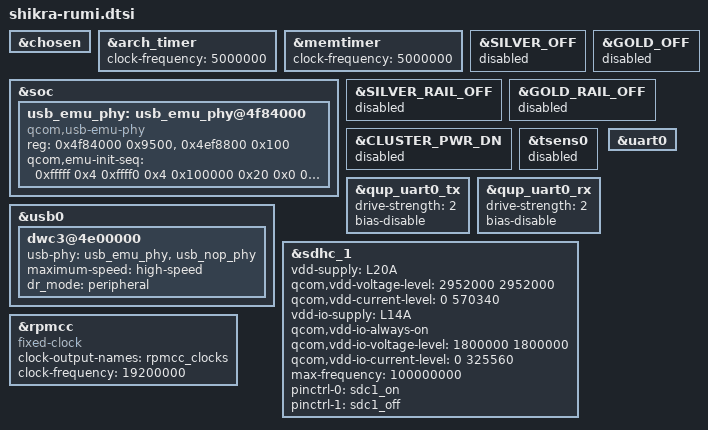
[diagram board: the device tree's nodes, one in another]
// SPDX-License-Identifier: BSD-3-Clause
/*
 * Copyright (c) Qualcomm Technologies, Inc. and/or its subsidiaries.
 */
&chosen {
};

&arch_timer {
	clock-frequency = <5000000>;
};

&memtimer {
	clock-frequency = <5000000>;
};

&soc {
	usb_emu_phy: usb_emu_phy@4f84000 {
		     compatible = "qcom,usb-emu-phy";
		     reg = <0x4f84000 0x9500>,
			 <0x4ef8800 0x100>;
		     reg-names = "base", "qscratch_base";

		     qcom,emu-init-seq = <0xfffff 0x4
			     0xffff0 0x4
			     0x100000 0x20
			     0x0 0x20
			     0x000101F0 0x20
			     0x00100000 0x3c
			     0x0 0x3c
			     0x0 0x4>;
	};
};

&SILVER_OFF {
	status = "disabled";
};

&SILVER_RAIL_OFF {
	status = "disabled";
};

&GOLD_OFF {
	status = "disabled";
};

&GOLD_RAIL_OFF {
	status = "disabled";
};

&CLUSTER_PWR_DN {
	status = "disabled";
};

&tsens0 {
	status = "disabled";
};

&qup_uart0_tx {
	drive-strength = <2>;
	bias-disable;
};

&qup_uart0_rx {
	drive-strength = <2>;
	bias-disable;
};

&uart0 {
	status = "okay";
};

&usb0 {
	dwc3@4e00000 {
		usb-phy = <&usb_emu_phy>, <&usb_nop_phy>;
		maximum-speed = "high-speed";
		dr_mode = "peripheral";
	};
};

&sdhc_1 {
	status = "okay";
	vdd-supply = <&L20A>;
	qcom,vdd-voltage-level = <2952000 2952000>;
	qcom,vdd-current-level = <0 570340>;

	vdd-io-supply = <&L14A>;
	qcom,vdd-io-always-on;
	qcom,vdd-io-voltage-level = <1800000 1800000>;
	qcom,vdd-io-current-level = <0 325560>;

	/delete-property/ mmc-ddr-1_8v;
	/delete-property/ mmc-hs200-1_8v;
	/delete-property/ mmc-hs400-1_8v;
	/delete-property/ mmc-hs400-enhanced-strobe;

	max-frequency = <100000000>;

	pinctrl-names = "default", "sleep";
	pinctrl-0 = <&sdc1_on>;
	pinctrl-1 = <&sdc1_off>;
};

&rpmcc {
	compatible = "fixed-clock";
	clock-output-names = "rpmcc_clocks";
	clock-frequency = <19200000>;
};
